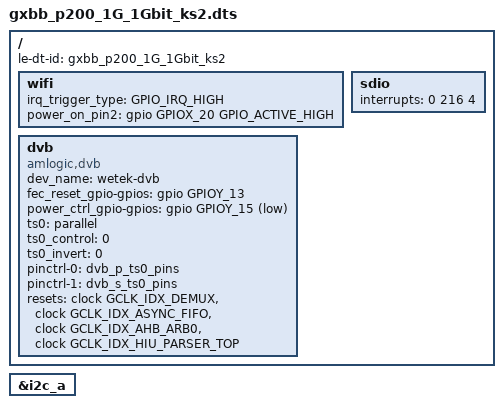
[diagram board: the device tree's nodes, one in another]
#include "gxbb_p200.dts"

/{
	le-dt-id = "gxbb_p200_1G_1Gbit_ks2";

	wifi {
		irq_trigger_type = "GPIO_IRQ_HIGH";
		/delete-property/ dhd_static_buf;
		power_on_pin2 = <&gpio	   GPIOX_20	   GPIO_ACTIVE_HIGH>;
	};

	sdio {
		interrupts = <	0 216 4>;
	};

	dvb {
		compatible = "amlogic,dvb";
		dev_name = "wetek-dvb";
		status = "okay";
		fec_reset_gpio-gpios = <&gpio GPIOY_13 GPIO_ACTIVE_HIGH>;
		power_ctrl_gpio-gpios = <&gpio GPIOY_15 GPIO_ACTIVE_LOW>;
		//"parallel","serial","disable"
		ts0 = "parallel";
		ts0_control = <0>;
		ts0_invert = <0>;
		pinctrl-names = "p_ts0", "s_ts0";
		pinctrl-0 = <&dvb_p_ts0_pins>;
		pinctrl-1 = <&dvb_s_ts0_pins>;
		resets = <&clock GCLK_IDX_DEMUX
				&clock GCLK_IDX_ASYNC_FIFO
				&clock GCLK_IDX_AHB_ARB0
				&clock GCLK_IDX_HIU_PARSER_TOP>;
		reset-names = "demux", "asyncfifo", "ahbarb0", "uparsertop";
	};
};

&i2c_a {
	status = "okay";
};


